AUTOSAR XML (schema 00048)
package /HuaweiMDC/FunctionalSoftware/CameraTrackerApplication/Execution
  executable CameraTrackerExecutable
    root sw component prototype CameraTrackerRootSwComponent: application-type=CameraTrackerApplicationSwComponent
package /HuaweiMDC/FunctionalSoftware/CameraTrackerApplication/SwComponent
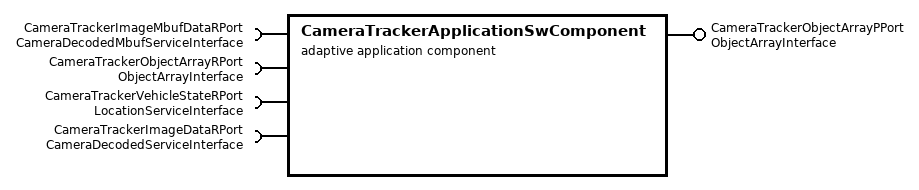
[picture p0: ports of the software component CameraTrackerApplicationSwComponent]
  adaptive application sw component type CameraTrackerApplicationSwComponent
    require port CameraTrackerImageMbufDataRPort: required-interface=CameraDecodedMbufServiceInterface
    provide port CameraTrackerObjectArrayPPort: provided-interface=ObjectArrayInterface
    require port CameraTrackerObjectArrayRPort: required-interface=ObjectArrayInterface
    require port CameraTrackerVehicleStateRPort: required-interface=LocationServiceInterface
    require port CameraTrackerImageDataRPort: required-interface=CameraDecodedServiceInterface
